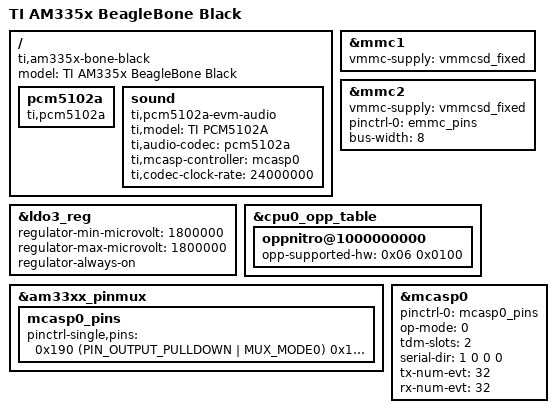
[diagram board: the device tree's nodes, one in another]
/*
 * Copyright (C) 2012 Texas Instruments Incorporated - http://www.ti.com/
 *
 * This program is free software; you can redistribute it and/or modify
 * it under the terms of the GNU General Public License version 2 as
 * published by the Free Software Foundation.
 */
/dts-v1/;

#include "am33xx.dtsi"
#include "am335x-bone-common.dtsi"
/* #include "am33xx-overlay-edma-fix.dtsi" */
#include <dt-bindings/display/tda998x.h>
/* #include "am335x-bone-jtag.dtsi" */

/* pruss: pick one: */

/*
 * /etc/modprobe.d/pruss-blacklist.conf
 *
 * blacklist uio_pruss
 */

/* #include "am33xx-pruss-rproc.dtsi" */

/*
 * /etc/modprobe.d/pruss-blacklist.conf
 *
 * blacklist pruss
 * blacklist pruss_intc
 * blacklist pru-rproc
 */

#include "am33xx-pruss-uio.dtsi"

/ {
	model = "TI AM335x BeagleBone Black";
	compatible = "ti,am335x-bone-black", "ti,am335x-bone", "ti,am33xx";
};

&ldo3_reg {
	regulator-min-microvolt = <1800000>;
	regulator-max-microvolt = <1800000>;
	regulator-always-on;
};

&mmc1 {
	vmmc-supply = <&vmmcsd_fixed>;
};

&mmc2 {
	vmmc-supply = <&vmmcsd_fixed>;
	pinctrl-names = "default";
	pinctrl-0 = <&emmc_pins>;
	bus-width = <8>;
	status = "okay";
};

&cpu0_opp_table {
	/*
	 * All PG 2.0 silicon may not support 1GHz but some of the early
	 * BeagleBone Blacks have PG 2.0 silicon which is guaranteed
	 * to support 1GHz OPP so enable it for PG 2.0 on this board.
	 */
	oppnitro@1000000000 {
		opp-supported-hw = <0x06 0x0100>;
	};
};

&am33xx_pinmux {
	mcasp0_pins: mcasp0_pins {
		pinctrl-single,pins = <
			0x190 (PIN_OUTPUT_PULLDOWN | MUX_MODE0)	/* mcasp0_aclkx */
			0x194 (PIN_OUTPUT_PULLDOWN | MUX_MODE0)	/* mcasp0_fsx*/
			0x198 (PIN_OUTPUT_PULLDOWN | MUX_MODE0)	/* mcasp0_axr0 */
		>;
	};
};
 
&mcasp0 {
		#sound-dai-cells = <0>;
		pinctrl-names = "default";
		pinctrl-0 = <&mcasp0_pins>;
		status = "okay";
		op-mode = <0>;          /* MCASP_IIS_MODE */
		tdm-slots = <2>;
		/* 16 serializer */
		serial-dir = <  /* 0: INACTIVE, 1: TX, 2: RX */
			1 0 0 0
		>;
		tx-num-evt = <32>;
		rx-num-evt = <32>;
};
 
/ {
 
	pcm5102a: pcm5102a {
		#sound-dai-cells = <0>;
		compatible = "ti,pcm5102a";
	};
 
	sound {
		compatible = "ti,pcm5102a-evm-audio";
		ti,model = "TI PCM5102A";
		ti,audio-codec = <&pcm5102a>;
		ti,mcasp-controller = <&mcasp0>;
		ti,codec-clock-rate = <24000000>;
	};
 
};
